# nrf54l20_enga_flpr register map
Vendor: Nordic Semiconductor; Series: nrf54l; File version: 1
Registers are 32-bit, read-write, reset 0x0 unless marked. A register's access mark holds for its fields unless they carry their own. Offsets are from the block's base; [hi:lo] are bit positions; lines under a group give offsets from that group; {n}, {i} and the like mark numbered series; 'fields as' and 'values as' point back to an identical list.

## GLOBAL_MEMCONF_NS — Memory configuration 0
Base 0x400CF000
Same registers: GLOBAL_MEMCONF_S 0x500CF000
{0x500+0x10*i} POWER[{i}] (i=0..1) group — Unspecified
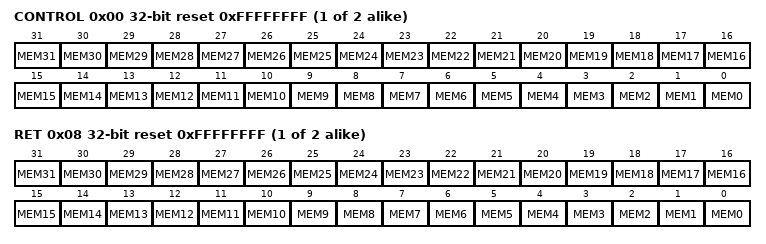
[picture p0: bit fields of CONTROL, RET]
  0x00 CONTROL reset 0xFFFFFFFF — Description cluster: Control memory block power.
    [all] fields
      0=Off (Power down); 1=On (Power up)
    [n] MEM{n} (n=0..31) — Keep the memory block MEM[{n}] on or off when in System ON mode.
  0x08 RET reset 0xFFFFFFFF — Description cluster: RAM retention for RAM [n].
    [all] fields
      0=Off (Retention off); 1=On (Retention on)
    [n] MEM{n} (n=0..31) — Keep the RAM block MEM[{n}] retained when in System OFF mode.

## GLOBAL_TEMP_NS — Temperature Sensor 0
Base 0x400D7000
Same registers: GLOBAL_TEMP_S 0x500D7000
0x00 TASKS_START wo — Start temperature measurement
  [0] TASKS_START
    1=Trigger task
0x04 TASKS_STOP wo — Stop temperature measurement
  [0] TASKS_STOP
    1=Trigger task
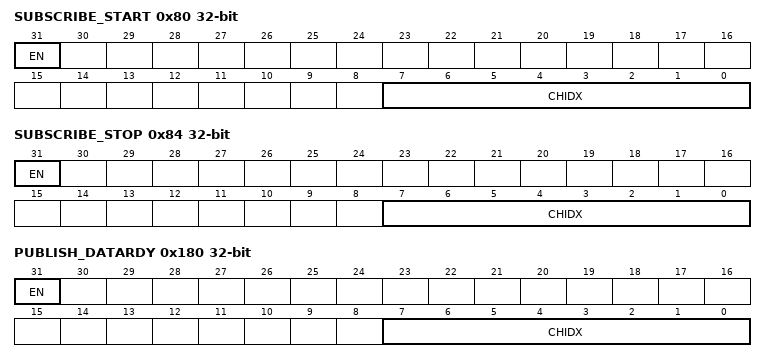
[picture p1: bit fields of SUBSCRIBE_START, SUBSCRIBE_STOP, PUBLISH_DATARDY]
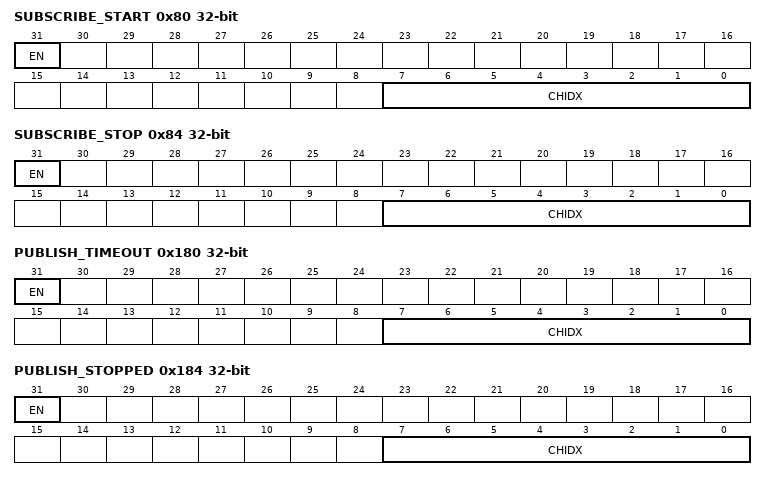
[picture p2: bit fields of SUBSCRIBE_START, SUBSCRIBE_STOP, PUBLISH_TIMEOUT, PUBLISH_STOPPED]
0x80 SUBSCRIBE_START — Subscribe configuration for task START
  [31] EN
    0=Disabled (Disable subscription); 1=Enabled (Enable subscription)
  [7:0] CHIDX — DPPI channel that task START will subscribe to
0x84 SUBSCRIBE_STOP — Subscribe configuration for task STOP
  [31] EN
    values as SUBSCRIBE_START.EN
  [7:0] CHIDX — DPPI channel that task STOP will subscribe to
0x100 EVENTS_DATARDY — Temperature measurement complete, data ready
  [0] EVENTS_DATARDY
    0=NotGenerated (Event not generated); 1=Generated (Event generated)
0x180 PUBLISH_DATARDY — Publish configuration for event DATARDY
  [31] EN
    0=Disabled (Disable publishing); 1=Enabled (Enable publishing)
  [7:0] CHIDX — DPPI channel that event DATARDY will publish to
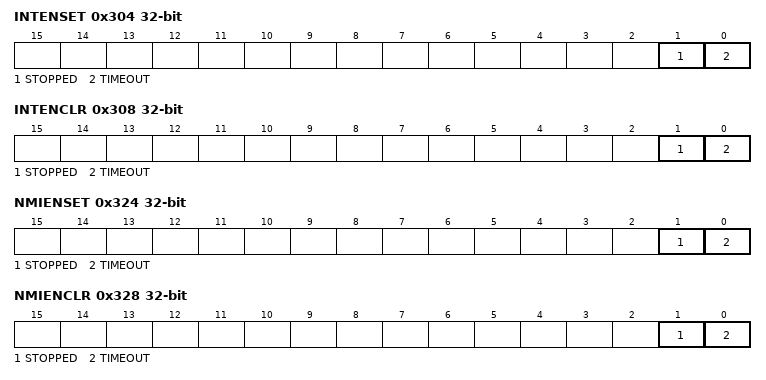
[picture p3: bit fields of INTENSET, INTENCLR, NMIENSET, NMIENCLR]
0x304 INTENSET — Enable interrupt
  [0] DATARDY — Write '1' to enable interrupt for event DATARDY
    on read: 0=Disabled (Read: Disabled); 1=Enabled (Read: Enabled) | on write: 1=Set (Enable)
0x308 INTENCLR — Disable interrupt
  [0] DATARDY — Write '1' to disable interrupt for event DATARDY
    on read: 0=Disabled (Read: Disabled); 1=Enabled (Read: Enabled) | on write: 1=Clear (Disable)
0x508 TEMP ro — Temperature in degC (0.25deg steps)
0x520 A0 reset 0x2D6 — Slope of 1st piece wise linear function
  [11:0] A0
0x524 A1 reset 0x32D — Slope of 2nd piece wise linear function
  [11:0] A1
0x528 A2 reset 0x384 — Slope of 3rd piece wise linear function
  [11:0] A2
0x52C A3 reset 0x3E9 — Slope of 4th piece wise linear function
  [11:0] A3
0x530 A4 reset 0x46F — Slope of 5th piece wise linear function
  [11:0] A4
0x534 A5 reset 0x522 — Slope of 6th piece wise linear function
  [11:0] A5
0x538 A6 reset 0x5B7 — Slope of 7th piece wise linear function
  [11:0] A6
0x540 B0 reset 0xFD6 — y-intercept of 1st piece wise linear function
  [11:0] B0
0x544 B1 reset 0xF76 — y-intercept of 2nd piece wise linear function
  [11:0] B1
0x548 B2 reset 0xF8A — y-intercept of 3rd piece wise linear function
  [11:0] B2
0x54C B3 reset 0xFF8 — y-intercept of 4th piece wise linear function
  [11:0] B3
0x550 B4 reset 0xCC — y-intercept of 5th piece wise linear function
  [11:0] B4
0x554 B5 reset 0x207 — y-intercept of 6th piece wise linear function
  [11:0] B5
0x558 B6 reset 0x558 — y-intercept of 7th piece wise linear function
  [11:0] B6
0x560 T0 reset 0xE2 — End point of 1st piece wise linear function
  [7:0] T0
0x564 T1 reset 0x2 — End point of 2nd piece wise linear function
  [7:0] T1
0x568 T2 reset 0x1F — End point of 3rd piece wise linear function
  [7:0] T2
0x56C T3 reset 0x38 — End point of 4th piece wise linear function
  [7:0] T3
0x570 T4 reset 0x4F — End point of 5th piece wise linear function
  [7:0] T4
0x574 T5 reset 0x66 — End point of 6th piece wise linear function
  [7:0] T5

## GLOBAL_WDT30_S — Watchdog Timer 0
Base 0x50108000
Same registers: GLOBAL_WDT31_NS 0x40109000, GLOBAL_WDT31_S 0x50109000
0x00 TASKS_START wo — Start WDT
  [0] TASKS_START
    1=Trigger task
0x04 TASKS_STOP wo — Stop WDT
  [0] TASKS_STOP
    1=Trigger task
0x80 SUBSCRIBE_START — Subscribe configuration for task START
  [31] EN
    0=Disabled (Disable subscription); 1=Enabled (Enable subscription)
  [7:0] CHIDX — DPPI channel that task START will subscribe to
0x84 SUBSCRIBE_STOP — Subscribe configuration for task STOP
  [31] EN
    values as SUBSCRIBE_START.EN
  [7:0] CHIDX — DPPI channel that task STOP will subscribe to
0x100 EVENTS_TIMEOUT — Watchdog timeout
  [0] EVENTS_TIMEOUT
    0=NotGenerated (Event not generated); 1=Generated (Event generated)
0x104 EVENTS_STOPPED — Watchdog stopped
  [0] EVENTS_STOPPED
    values as EVENTS_TIMEOUT.EVENTS_TIMEOUT
0x180 PUBLISH_TIMEOUT — Publish configuration for event TIMEOUT
  [31] EN
    0=Disabled (Disable publishing); 1=Enabled (Enable publishing)
  [7:0] CHIDX — DPPI channel that event TIMEOUT will publish to
0x184 PUBLISH_STOPPED — Publish configuration for event STOPPED
  [31] EN
    values as PUBLISH_TIMEOUT.EN
  [7:0] CHIDX — DPPI channel that event STOPPED will publish to
0x304 INTENSET — Enable interrupt
  [1] STOPPED — Write '1' to enable interrupt for event STOPPED
    on read: 0=Disabled (Read: Disabled); 1=Enabled (Read: Enabled) | on write: 1=Set (Enable)
  [0] TIMEOUT — Write '1' to enable interrupt for event TIMEOUT
    values as STOPPED
0x308 INTENCLR — Disable interrupt
  [1] STOPPED — Write '1' to disable interrupt for event STOPPED
    on read: 0=Disabled (Read: Disabled); 1=Enabled (Read: Enabled) | on write: 1=Clear (Disable)
  [0] TIMEOUT — Write '1' to disable interrupt for event TIMEOUT
    values as STOPPED
0x324 NMIENSET — Enable interrupt
  fields as INTENSET
0x328 NMIENCLR — Disable interrupt
  fields as INTENCLR
0x400 RUNSTATUS ro
  [0] RUNSTATUSWDT — Indicates whether or not WDT is running
    0=NotRunning (Watchdog is not running); 1=Running (Watchdog is running)
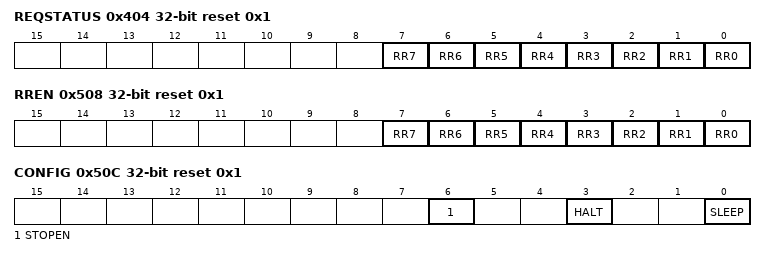
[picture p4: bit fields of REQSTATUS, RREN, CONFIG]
0x404 REQSTATUS ro reset 0x1 — Request status
  [n] RR{n} (n=0..7) — Request status for RR[{n}] register
    0=DisabledOrRequested (RR[{n}] register is not enabled, or are already requesting reload); 1=EnabledAndUnrequested (RR[{n}] register is enabled, and are not yet requesting reload)
0x504 CRV reset 0xFFFFFFFF — Counter reload value
  [31:0] CRV — Counter reload value in number of cycles of the 32.768 kHz clock
0x508 RREN reset 0x1 — Enable register for reload request registers
  [n] RR{n} (n=0..7) — Enable or disable RR[{n}] register
    0=Disabled (Disable RR[{n}] register); 1=Enabled (Enable RR[{n}] register)
0x50C CONFIG reset 0x1 — Configuration register
  [6] STOPEN — Allow stopping WDT
    0=Disable (Do not allow stopping WDT); 1=Enable (Allow stopping WDT)
  [3] HALT — Configure WDT to either be paused, or kept running, while the CPU is halted by the debugger
    0=Pause WDT while the CPU is halted by the debugger; 1=Run (Keep WDT running while the CPU is halted by the debugger)
  [0] SLEEP — Configure WDT to either be paused, or kept running, while the CPU is sleeping
    0=Pause WDT while the CPU is sleeping; 1=Run (Keep WDT running while the CPU is sleeping)
0x520 TSEN wo — Task stop enable
  [31:0] TSEN — Allow stopping WDT
    0x6E524635=Enable (Value to allow stopping WDT)
{0x600+4i} RR[{i}] (i=0..7) wo — Description collection: Reload request n
  [31:0] RR — Reload request register
    0x6E524635=Reload (Value to request a reload of the watchdog timer)

## Notices in the file
Copyright (c) 2010 - 2025, Nordic Semiconductor ASA All rights reserved.
SPDX-License-Identifier: BSD-3-Clause
Redistribution and use in source and binary forms, with or without
modification, are permitted provided that the following conditions are met:
1. Redistributions of source code must retain the above copyright notice, this
list of conditions and the following disclaimer.
2. Redistributions in binary form must reproduce the above copyright
notice, this list of conditions and the following disclaimer in the
documentation and/or other materials provided with the distribution.
3. Neither the name of Nordic Semiconductor ASA nor the names of its
contributors may be used to endorse or promote products derived from this
software without specific prior written permission.
THIS SOFTWARE IS PROVIDED BY THE COPYRIGHT HOLDERS AND CONTRIBUTORS "AS IS"
AND ANY EXPRESS OR IMPLIED WARRANTIES, INCLUDING, BUT NOT LIMITED TO, THE
IMPLIED WARRANTIES OF MERCHANTABILITY, AND FITNESS FOR A PARTICULAR PURPOSE
ARE DISCLAIMED. IN NO EVENT SHALL NORDIC SEMICONDUCTOR ASA OR CONTRIBUTORS BE
LIABLE FOR ANY DIRECT, INDIRECT, INCIDENTAL, SPECIAL, EXEMPLARY, OR
CONSEQUENTIAL DAMAGES (INCLUDING, BUT NOT LIMITED TO, PROCUREMENT OF
SUBSTITUTE GOODS OR SERVICES; LOSS OF USE, DATA, OR PROFITS; OR BUSINESS
INTERRUPTION) HOWEVER CAUSED AND ON ANY THEORY OF LIABILITY, WHETHER IN
CONTRACT, STRICT LIABILITY, OR TORT (INCLUDING NEGLIGENCE OR OTHERWISE)
ARISING IN ANY WAY OUT OF THE USE OF THIS SOFTWARE, EVEN IF ADVISED OF THE
POSSIBILITY OF SUCH DAMAGE.
